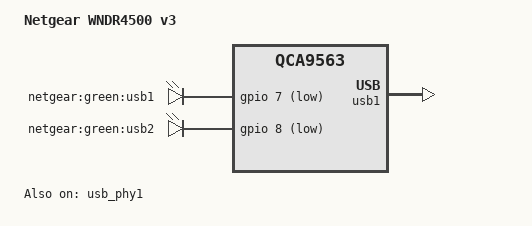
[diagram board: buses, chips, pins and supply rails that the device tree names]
// SPDX-License-Identifier: GPL-2.0-or-later OR MIT

/dts-v1/;

#include "qca9563_netgear_wndr.dtsi"

/ {
	compatible = "netgear,wndr4500-v3", "qca,qca9563";
	model = "Netgear WNDR4500 v3";
};

&leds {
	usb1_green {
		label = "netgear:green:usb1";
		gpios = <&gpio 7 GPIO_ACTIVE_LOW>;
		trigger-sources = <&hub_port0>;
		linux,default-trigger = "usbport";
	};

	usb2_green {
		label = "netgear:green:usb2";
		gpios = <&gpio 8 GPIO_ACTIVE_LOW>;
		trigger-sources = <&hub_port1>;
		linux,default-trigger = "usbport";
	};
};

&usb_phy1 {
	status = "okay";
};

&usb1 {
	#address-cells = <1>;
	#size-cells = <0>;
	status = "okay";

	hub_port1: port@1 {
		reg = <1>;
		#trigger-source-cells = <0>;
	};
};
